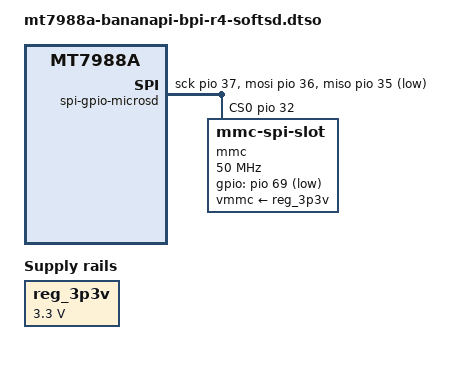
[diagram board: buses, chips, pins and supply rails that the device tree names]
// SPDX-License-Identifier: (GPL-2.0 OR MIT)
/*
 * Copyright (C) 2023 Daniel Golle <daniel@makrotopia.org>
 *
 * not working yet...
 */

/dts-v1/;
/plugin/;

#include <dt-bindings/gpio/gpio.h>

/ {
	compatible = "bananapi,bpi-r4", "mediatek,mt7988a";

	fragment@0 {
		target-path = "/";
		__overlay__ {
			reg_3p3v: regulator-3p3v {
				compatible = "regulator-fixed";
				regulator-name = "fixed-3.3V";
				regulator-min-microvolt = <3300000>;
				regulator-max-microvolt = <3300000>;
				regulator-boot-on;
				regulator-always-on;
			};

			spi-gpio-microsd {
				compatible = "spi-gpio";
				#address-cells = <1>;
				#size-cells = <0>;
				sck-gpios = <&pio 37 GPIO_ACTIVE_HIGH>;
				miso-gpios = <&pio 35 GPIO_ACTIVE_LOW>;
				mosi-gpios = <&pio 36 GPIO_ACTIVE_HIGH>;
				cs-gpios = <&pio 32 GPIO_ACTIVE_HIGH>;
				num-chipselects = <1>;

				mmc@0 {
					compatible = "mmc-spi-slot";
					#address-cells = <1>;
					#size-cells = <0>;
					reg = <0>;
					gpios = <&pio 69 GPIO_ACTIVE_LOW>;
					voltage-ranges = <3300 3300>;
					spi-max-frequency = <50000000>;
					vmmc-supply = <&reg_3p3v>;
				};
			};
		};
	};

};
